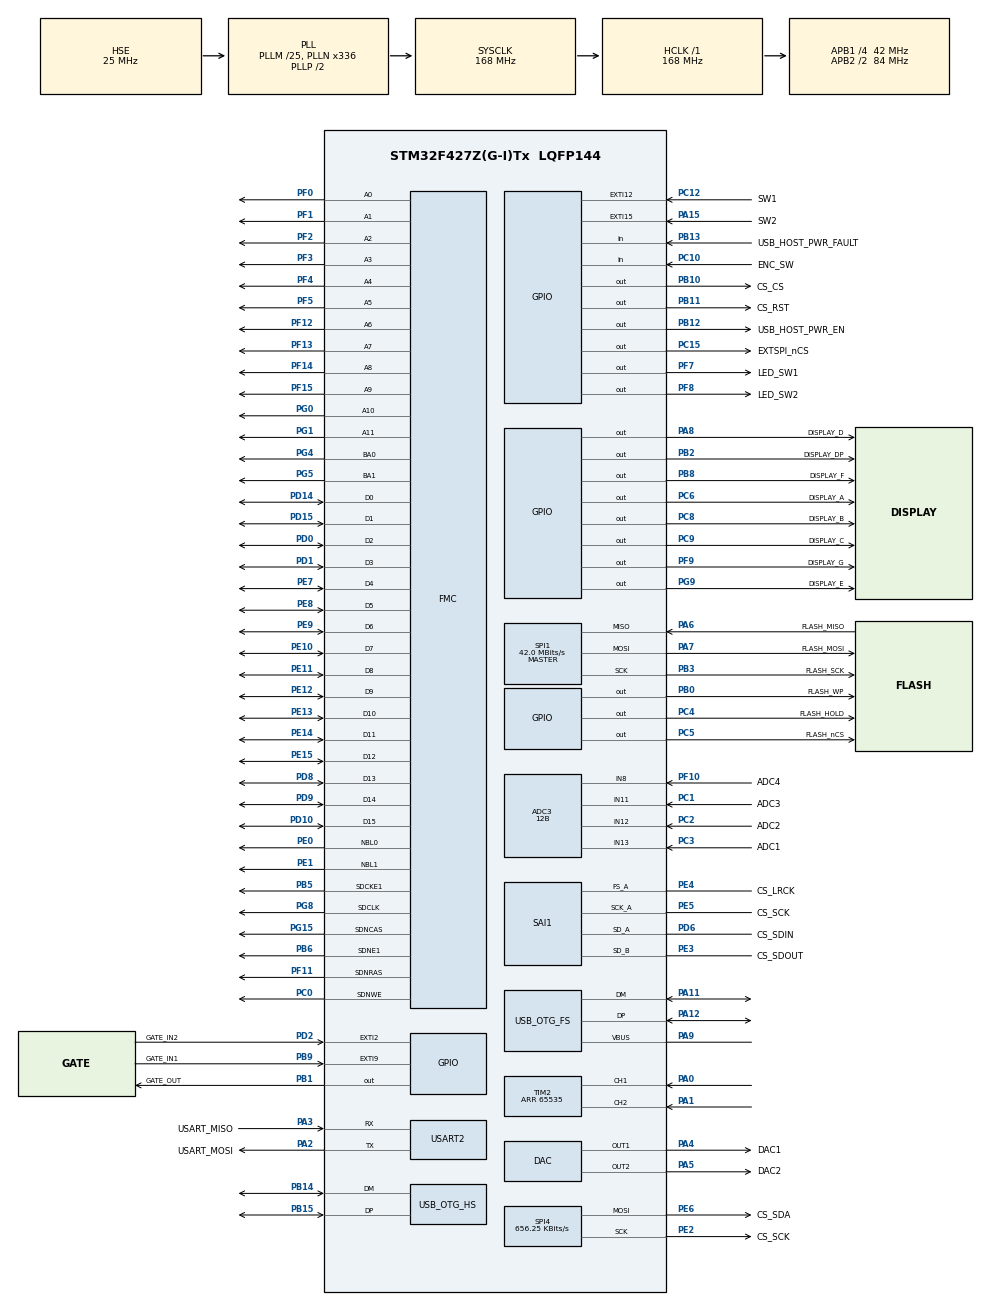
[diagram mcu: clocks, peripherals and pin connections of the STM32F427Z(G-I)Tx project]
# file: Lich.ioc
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ADC3.Channel-31\#ChannelRegularConversion=ADC_CHANNEL_13
ADC3.Channel-32\#ChannelRegularConversion=ADC_CHANNEL_12
ADC3.Channel-33\#ChannelRegularConversion=ADC_CHANNEL_11
ADC3.Channel-34\#ChannelRegularConversion=ADC_CHANNEL_8
ADC3.ClockPrescaler=ADC_CLOCK_SYNC_PCLK_DIV8
ADC3.ContinuousConvMode=ENABLE
ADC3.DMAContinuousRequests=ENABLE
ADC3.DataAlign=ADC_DATAALIGN_RIGHT
ADC3.DiscontinuousConvMode=DISABLE
ADC3.EOCSelection=ADC_EOC_SEQ_CONV
ADC3.EnableAnalogWatchDog=false
ADC3.ExternalTrigConv=ADC_SOFTWARE_START
ADC3.ExternalTrigConvEdge=ADC_EXTERNALTRIGCONVEDGE_NONE
ADC3.InjNumberOfConversion=0
ADC3.NbrOfConversion=4
ADC3.NbrOfConversionFlag=1
ADC3.Rank-31\#ChannelRegularConversion=1
ADC3.Rank-32\#ChannelRegularConversion=2
ADC3.Rank-33\#ChannelRegularConversion=3
ADC3.Rank-34\#ChannelRegularConversion=4
ADC3.Resolution=ADC_RESOLUTION_12B
ADC3.SamplingTime-31\#ChannelRegularConversion=ADC_SAMPLETIME_144CYCLES
ADC3.SamplingTime-32\#ChannelRegularConversion=ADC_SAMPLETIME_144CYCLES
ADC3.SamplingTime-33\#ChannelRegularConversion=ADC_SAMPLETIME_144CYCLES
ADC3.SamplingTime-34\#ChannelRegularConversion=ADC_SAMPLETIME_144CYCLES
ADC3.ScanConvMode=ENABLE
Dma.ADC3.2.Direction=DMA_PERIPH_TO_MEMORY
Dma.ADC3.2.FIFOMode=DMA_FIFOMODE_DISABLE
Dma.ADC3.2.Instance=DMA2_Stream0
Dma.ADC3.2.MemDataAlignment=DMA_MDATAALIGN_HALFWORD
Dma.ADC3.2.MemInc=DMA_MINC_ENABLE
Dma.ADC3.2.Mode=DMA_CIRCULAR
Dma.ADC3.2.PeriphDataAlignment=DMA_PDATAALIGN_HALFWORD
Dma.ADC3.2.PeriphInc=DMA_PINC_DISABLE
Dma.ADC3.2.Priority=DMA_PRIORITY_LOW
Dma.Request0=SAI1_A
Dma.Request1=SAI1_B
Dma.Request2=ADC3
Dma.Request3=USART2_RX
Dma.Request4=USART2_TX
Dma.SAI1_A.0.Direction=DMA_MEMORY_TO_PERIPH
Dma.SAI1_A.0.FIFOMode=DMA_FIFOMODE_DISABLE
Dma.SAI1_A.0.Instance=DMA2_Stream1
Dma.SAI1_A.0.MemDataAlignment=DMA_MDATAALIGN_WORD
Dma.SAI1_A.0.MemInc=DMA_MINC_ENABLE
Dma.SAI1_A.0.Mode=DMA_CIRCULAR
Dma.SAI1_A.0.PeriphDataAlignment=DMA_PDATAALIGN_WORD
Dma.SAI1_A.0.PeriphInc=DMA_PINC_DISABLE
Dma.SAI1_A.0.Priority=DMA_PRIORITY_VERY_HIGH
Dma.SAI1_B.1.Direction=DMA_PERIPH_TO_MEMORY
Dma.SAI1_B.1.FIFOMode=DMA_FIFOMODE_DISABLE
Dma.SAI1_B.1.Instance=DMA2_Stream4
Dma.SAI1_B.1.MemDataAlignment=DMA_MDATAALIGN_WORD
Dma.SAI1_B.1.MemInc=DMA_MINC_ENABLE
Dma.SAI1_B.1.Mode=DMA_CIRCULAR
Dma.SAI1_B.1.PeriphDataAlignment=DMA_PDATAALIGN_WORD
Dma.SAI1_B.1.PeriphInc=DMA_PINC_DISABLE
Dma.SAI1_B.1.Priority=DMA_PRIORITY_VERY_HIGH
Dma.USART2_RX.3.Direction=DMA_PERIPH_TO_MEMORY
Dma.USART2_RX.3.FIFOMode=DMA_FIFOMODE_DISABLE
Dma.USART2_RX.3.Instance=DMA1_Stream5
Dma.USART2_RX.3.MemDataAlignment=DMA_MDATAALIGN_BYTE
Dma.USART2_RX.3.MemInc=DMA_MINC_ENABLE
Dma.USART2_RX.3.Mode=DMA_NORMAL
Dma.USART2_RX.3.PeriphDataAlignment=DMA_PDATAALIGN_BYTE
Dma.USART2_RX.3.PeriphInc=DMA_PINC_DISABLE
Dma.USART2_RX.3.Priority=DMA_PRIORITY_LOW
Dma.USART2_TX.4.Direction=DMA_MEMORY_TO_PERIPH
Dma.USART2_TX.4.FIFOMode=DMA_FIFOMODE_DISABLE
Dma.USART2_TX.4.Instance=DMA1_Stream6
Dma.USART2_TX.4.MemDataAlignment=DMA_MDATAALIGN_BYTE
Dma.USART2_TX.4.MemInc=DMA_MINC_ENABLE
Dma.USART2_TX.4.Mode=DMA_NORMAL
Dma.USART2_TX.4.PeriphDataAlignment=DMA_PDATAALIGN_BYTE
Dma.USART2_TX.4.PeriphInc=DMA_PINC_DISABLE
Dma.USART2_TX.4.Priority=DMA_PRIORITY_LOW
FMC.CASLatency1=FMC_SDRAM_CAS_LATENCY_3
FMC.ExitSelfRefreshDelay1=6
FMC.LoadToActiveDelay1=2
FMC.RCDDelay1=2
FMC.RPDelay1=2
FMC.RPDelay2=2
FMC.ReadBurst1=FMC_SDRAM_RBURST_ENABLE
FMC.ReadBurst2=FMC_SDRAM_RBURST_ENABLE
FMC.ReadPipeDelay1=FMC_SDRAM_RPIPE_DELAY_0
FMC.RowCycleDelay1=6
FMC.RowCycleDelay2=6
FMC.SDClockPeriod1=FMC_SDRAM_CLOCK_PERIOD_2
FMC.SDClockPeriod2=FMC_SDRAM_CLOCK_PERIOD_2
FMC.SelfRefreshTime1=4
FMC.WriteRecoveryTime1=2
FREERTOS.INCLUDE_vTaskDelayUntil=1
FREERTOS.MEMORY_ALLOCATION=2
FREERTOS.Tasks01=defaultTask,0,1024,StartDefaultTask,Default,NULL,Dynamic,NULL,NULL
FREERTOS.configCHECK_FOR_STACK_OVERFLOW=2
FREERTOS.configENABLE_BACKWARD_COMPATIBILITY=0
FREERTOS.configTOTAL_HEAP_SIZE=8192
FREERTOS.configUSE_MALLOC_FAILED_HOOK=1
FREERTOS.configUSE_MUTEXES=0
FREERTOS.configUSE_PREEMPTION=0
Mcu.Family=STM32F4
Mcu.Name=STM32F427Z(G-I)Tx
Mcu.Package=LQFP144
NVIC.DMA1_Stream5_IRQn=true\:5\:0\:false\:false\:true\:true\:false\:true
NVIC.DMA1_Stream6_IRQn=true\:5\:0\:false\:false\:true\:true\:false\:true
NVIC.DMA2_Stream0_IRQn=true\:10\:0\:true\:false\:true\:true\:true\:true
NVIC.DMA2_Stream1_IRQn=true\:5\:0\:true\:false\:true\:true\:true\:true
NVIC.DMA2_Stream4_IRQn=true\:5\:0\:true\:false\:true\:true\:true\:true
NVIC.EXTI15_10_IRQn=true\:10\:0\:true\:false\:true\:true\:true\:true
NVIC.EXTI2_IRQn=true\:10\:0\:true\:false\:true\:true\:true\:true
NVIC.EXTI9_5_IRQn=true\:10\:0\:true\:false\:true\:true\:true\:true
NVIC.OTG_FS_IRQn=true\:5\:0\:false\:false\:true\:true\:true\:true
NVIC.OTG_HS_IRQn=true\:8\:0\:true\:false\:true\:true\:true\:true
NVIC.PriorityGroup=NVIC_PRIORITYGROUP_4
NVIC.SAI1_IRQn=true\:5\:0\:true\:false\:true\:true\:true\:true
NVIC.USART2_IRQn=true\:5\:0\:false\:false\:true\:true\:true\:true
PA0/WKUP.GPIO_PuPd=GPIO_PULLUP
PA0/WKUP.Signal=S_TIM2_CH1_ETR
PA1.GPIO_PuPd=GPIO_PULLUP
PA1.Signal=S_TIM2_CH2
PA11.Mode=Device_Only
PA11.Signal=USB_OTG_FS_DM
PA12.Mode=Device_Only
PA12.Signal=USB_OTG_FS_DP
PA13.GPIO_Label=SWDIO
PA13.Mode=Serial_Wire
PA13.Signal=SYS_JTMS-SWDIO
PA14.GPIO_Label=SWCLK
PA14.Mode=Serial_Wire
PA14.Signal=SYS_JTCK-SWCLK
PA15.GPIO_Label=SW2
PA15.GPIO_ModeDefaultEXTI=GPIO_MODE_IT_RISING_FALLING
PA15.GPIO_PuPd=GPIO_PULLUP
PA15.Signal=GPXTI15
PA2.GPIO_Label=USART_MOSI
PA2.Mode=Asynchronous
PA2.Signal=USART2_TX
PA3.GPIO_Label=USART_MISO
PA3.Mode=Asynchronous
PA3.Signal=USART2_RX
PA4.GPIO_Label=DAC1
PA4.Signal=COMP_DAC1_group
PA5.GPIO_Label=DAC2
PA5.Signal=COMP_DAC2_group
PA6.GPIO_Label=FLASH_MISO
PA6.Mode=Full_Duplex_Master
PA6.Signal=SPI1_MISO
PA7.GPIO_Label=FLASH_MOSI
PA7.Mode=Full_Duplex_Master
PA7.Signal=SPI1_MOSI
PA8.GPIO_Label=DISPLAY_D
PA8.Signal=GPIO_Output
PA9.Mode=Activate_VBUS
PA9.Signal=USB_OTG_FS_VBUS
PB0.GPIO_Label=FLASH_WP
PB0.Signal=GPIO_Output
PB1.GPIO_Label=GATE_OUT
PB1.Signal=GPIO_Output
PB10.GPIO_Label=CS_CS
PB10.Signal=GPIO_Output
PB11.GPIO_Label=CS_RST
PB11.Signal=GPIO_Output
PB12.GPIO_Label=USB_HOST_PWR_EN
PB12.Signal=GPIO_Output
PB13.GPIO_Label=USB_HOST_PWR_FAULT
PB13.Signal=GPIO_Input
PB14.Mode=Host_FS
PB14.Signal=USB_OTG_HS_DM
PB15.Mode=Host_FS
PB15.Signal=USB_OTG_HS_DP
PB2/BOOT1.GPIO_Label=DISPLAY_DP
PB2/BOOT1.Signal=GPIO_Output
PB3.GPIO_Label=FLASH_SCK
PB3.Mode=Full_Duplex_Master
PB3.Signal=SPI1_SCK
PB5.Mode=SdramChipSelect2_1
PB5.Signal=FMC_SDCKE1
PB6.Mode=SdramChipSelect2_1
PB6.Signal=FMC_SDNE1
PB8.GPIO_Label=DISPLAY_F
PB8.Signal=GPIO_Output
PB9.GPIO_Label=GATE_IN1
PB9.GPIO_ModeDefaultEXTI=GPIO_MODE_IT_RISING_FALLING
PB9.GPIO_PuPd=GPIO_PULLUP
PB9.Signal=GPXTI9
PC0.Signal=FMC_SDNWE
PC1.GPIO_Label=ADC3
PC1.Signal=ADCx_IN11
PC10.GPIO_Label=ENC_SW
PC10.GPIO_PuPd=GPIO_PULLUP
PC10.Signal=GPIO_Input
PC12.GPIO_Label=SW1
PC12.GPIO_ModeDefaultEXTI=GPIO_MODE_IT_RISING_FALLING
PC12.GPIO_PuPd=GPIO_PULLUP
PC12.Signal=GPXTI12
PC15/OSC32_OUT.GPIO_Label=EXTSPI_nCS
PC15/OSC32_OUT.Signal=GPIO_Output
PC2.GPIO_Label=ADC2
PC2.Signal=ADCx_IN12
PC3.GPIO_Label=ADC1
PC3.Signal=ADCx_IN13
PC4.GPIO_Label=FLASH_HOLD
PC4.Signal=GPIO_Output
PC5.GPIO_Label=FLASH_nCS
PC5.Signal=GPIO_Output
PC6.GPIO_Label=DISPLAY_A
PC6.PinState=GPIO_PIN_SET
PC6.Signal=GPIO_Output
PC8.GPIO_Label=DISPLAY_B
PC8.Signal=GPIO_Output
PC9.GPIO_Label=DISPLAY_C
PC9.Signal=GPIO_Output
PD0.Signal=FMC_D2_DA2
PD1.Signal=FMC_D3_DA3
PD10.Signal=FMC_D15_DA15
PD14.Signal=FMC_D0_DA0
PD15.Signal=FMC_D1_DA1
PD2.GPIO_Label=GATE_IN2
PD2.GPIO_ModeDefaultEXTI=GPIO_MODE_IT_RISING_FALLING
PD2.GPIO_PuPd=GPIO_PULLUP
PD2.Signal=GPXTI2
PD6.GPIO_Label=CS_SDIN
PD6.Mode=SAI_A_AsyncSlave
PD6.Signal=SAI1_SD_A
PD8.Signal=FMC_D13_DA13
PD9.Signal=FMC_D14_DA14
PE0.Signal=FMC_NBL0
PE1.Signal=FMC_NBL1
PE10.Signal=FMC_D7_DA7
PE11.Signal=FMC_D8_DA8
PE12.Signal=FMC_D9_DA9
PE13.Signal=FMC_D10_DA10
PE14.Signal=FMC_D11_DA11
PE15.Signal=FMC_D12_DA12
PE2.GPIO_Label=CS_SCK
PE2.Mode=TX_Only_Simplex_Unidirect_Master
PE2.Signal=SPI4_SCK
PE3.GPIO_Label=CS_SDOUT
PE3.Mode=SAI_B_SyncSlave
PE3.Signal=SAI1_SD_B
PE4.GPIO_Label=CS_LRCK
PE4.Mode=SAI_A_AsyncSlave
PE4.Signal=SAI1_FS_A
PE5.GPIO_Label=CS_SCK
PE5.Mode=SAI_A_AsyncSlave
PE5.Signal=SAI1_SCK_A
PE6.GPIO_Label=CS_SDA
PE6.Mode=TX_Only_Simplex_Unidirect_Master
PE6.Signal=SPI4_MOSI
PE7.Signal=FMC_D4_DA4
PE8.Signal=FMC_D5_DA5
PE9.Signal=FMC_D6_DA6
PF0.Signal=FMC_A0
PF1.Signal=FMC_A1
PF10.GPIO_Label=ADC4
PF10.Mode=IN8
PF10.Signal=ADC3_IN8
PF11.Signal=FMC_SDNRAS
PF12.Signal=FMC_A6
PF13.Signal=FMC_A7
PF14.Signal=FMC_A8
PF15.Signal=FMC_A9
PF2.Signal=FMC_A2
PF3.Signal=FMC_A3
PF4.Signal=FMC_A4
PF5.Signal=FMC_A5
PF7.GPIO_Label=LED_SW1
PF7.Signal=GPIO_Output
PF8.GPIO_Label=LED_SW2
PF8.Signal=GPIO_Output
PF9.GPIO_Label=DISPLAY_G
PF9.Signal=GPIO_Output
PG0.Signal=FMC_A10
PG1.Signal=FMC_A11
PG15.Signal=FMC_SDNCAS
PG4.Signal=FMC_A14_BA0
PG5.Signal=FMC_A15_BA1
PG8.Signal=FMC_SDCLK
PG9.GPIO_Label=DISPLAY_E
PG9.Signal=GPIO_Output
PH0/OSC_IN.GPIO_Label=OSC1
PH0/OSC_IN.Mode=HSE-External-Oscillator
PH0/OSC_IN.Signal=RCC_OSC_IN
PH1/OSC_OUT.GPIO_Label=OSC2
PH1/OSC_OUT.Mode=HSE-External-Oscillator
PH1/OSC_OUT.Signal=RCC_OSC_OUT
ProjectManager.HeapSize=0x200
ProjectManager.StackSize=0x400
ProjectManager.TargetToolchain=Other Toolchains (GPDSC)
RCC.48MHZClocksFreq_Value=48000000
RCC.AHBFreq_Value=168000000
RCC.APB1CLKDivider=RCC_HCLK_DIV4
RCC.APB1Freq_Value=42000000
RCC.APB1TimFreq_Value=84000000
RCC.APB2CLKDivider=RCC_HCLK_DIV2
RCC.APB2Freq_Value=84000000
RCC.APB2TimFreq_Value=168000000
RCC.CortexFreq_Value=168000000
RCC.HCLKFreq_Value=168000000
RCC.HSE_VALUE=25000000
RCC.HSI_VALUE=16000000
RCC.LSE_VALUE=32768
RCC.PLLM=25
RCC.PLLN=336
RCC.PLLQ=7
RCC.PLLSAIN=100
RCC.SYSCLKFreq_VALUE=168000000
RCC.SYSCLKSource=RCC_SYSCLKSOURCE_PLLCLK
RCC.USBFreq_Value=48000000
RCC.VCOOutputFreq_Value=336000000
SAI1.AudioMode-SAI_A_AsyncSlave=SAI_MODESLAVE_TX
SAI1.AudioMode-SAI_B_SyncSlave=SAI_MODESLAVE_RX
SAI1.DataSize-SAI_A_AsyncSlave=SAI_DATASIZE_24
SAI1.FSDefinition-SAI_A_AsyncSlave=SAI_FS_CHANNEL_IDENTIFICATION
SAI1.FSDefinition-SAI_B_SyncSlave=SAI_FS_CHANNEL_IDENTIFICATION
SAI1.FrameLength-SAI_A_AsyncSlave=64
SAI1.FrameLength-SAI_B_SyncSlave=64
SAI1.Instance-SAI_A_AsyncSlave=SAI$Index_Block_A
SAI1.Instance-SAI_B_SyncSlave=SAI$Index_Block_B
SAI1.SlotNumber-SAI_A_AsyncSlave=2
SAI1.SlotSize-SAI_A_AsyncSlave=SAI_SLOTSIZE_32B
SAI1.SlotSize-SAI_B_SyncSlave=SAI_SLOTSIZE_32B
SAI1.Synchro-SAI_A_AsyncSlave=SAI_ASYNCHRONOUS
SAI1.Synchro-SAI_B_SyncSlave=SAI_SYNCHRONOUS
SAI1.Synchro_A=SAI_ASYNCHRONOUS
SAI1.Synchro_B=SAI_SYNCHRONOUS
SAI1.VirtualMode-SAI_A_AsyncSlave=VM_SLAVE
SAI1.VirtualMode-SAI_B_SyncSlave=VM_SLAVE
SH.ADCx_IN11.0=ADC3_IN11,IN11
SH.ADCx_IN12.0=ADC3_IN12,IN12
SH.ADCx_IN13.0=ADC3_IN13,IN13
SH.COMP_DAC1_group.0=DAC_OUT1,DAC_OUT1
SH.COMP_DAC2_group.0=DAC_OUT2,DAC_OUT2
SH.FMC_A0.0=FMC_A0,12b-sda1
SH.FMC_A1.0=FMC_A1,12b-sda1
SH.FMC_A10.0=FMC_A10,12b-sda1
SH.FMC_A11.0=FMC_A11,12b-sda1
SH.FMC_A14_BA0.0=FMC_BA0,FourSdramBanks1
SH.FMC_A15_BA1.0=FMC_BA1,FourSdramBanks1
SH.FMC_A2.0=FMC_A2,12b-sda1
SH.FMC_A3.0=FMC_A3,12b-sda1
SH.FMC_A4.0=FMC_A4,12b-sda1
SH.FMC_A5.0=FMC_A5,12b-sda1
SH.FMC_A6.0=FMC_A6,12b-sda1
SH.FMC_A7.0=FMC_A7,12b-sda1
SH.FMC_A8.0=FMC_A8,12b-sda1
SH.FMC_A9.0=FMC_A9,12b-sda1
SH.FMC_D0_DA0.0=FMC_D0,sd-16b-d1
SH.FMC_D10_DA10.0=FMC_D10,sd-16b-d1
SH.FMC_D11_DA11.0=FMC_D11,sd-16b-d1
SH.FMC_D12_DA12.0=FMC_D12,sd-16b-d1
SH.FMC_D13_DA13.0=FMC_D13,sd-16b-d1
SH.FMC_D14_DA14.0=FMC_D14,sd-16b-d1
SH.FMC_D15_DA15.0=FMC_D15,sd-16b-d1
SH.FMC_D1_DA1.0=FMC_D1,sd-16b-d1
SH.FMC_D2_DA2.0=FMC_D2,sd-16b-d1
SH.FMC_D3_DA3.0=FMC_D3,sd-16b-d1
SH.FMC_D4_DA4.0=FMC_D4,sd-16b-d1
SH.FMC_D5_DA5.0=FMC_D5,sd-16b-d1
SH.FMC_D6_DA6.0=FMC_D6,sd-16b-d1
SH.FMC_D7_DA7.0=FMC_D7,sd-16b-d1
SH.FMC_D8_DA8.0=FMC_D8,sd-16b-d1
SH.FMC_D9_DA9.0=FMC_D9,sd-16b-d1
SH.FMC_NBL0.0=FMC_NBL0,Sd2ByteEnable1
SH.FMC_NBL1.0=FMC_NBL1,Sd2ByteEnable1
SH.FMC_SDCLK.0=FMC_SDCLK,12b-sda1
SH.FMC_SDNCAS.0=FMC_SDNCAS,12b-sda1
SH.FMC_SDNRAS.0=FMC_SDNRAS,12b-sda1
SH.FMC_SDNWE.0=FMC_SDNWE,12b-sda1
SH.S_TIM2_CH1_ETR.0=TIM2_CH1,Encoder_Interface
SH.S_TIM2_CH2.0=TIM2_CH2,Encoder_Interface
SPI1.CalculateBaudRate=42.0 MBits/s
SPI1.Direction=SPI_DIRECTION_2LINES
SPI1.Mode=SPI_MODE_MASTER
SPI1.VirtualType=VM_MASTER
SPI4.BaudRatePrescaler=SPI_BAUDRATEPRESCALER_128
SPI4.CalculateBaudRate=656.25 KBits/s
SPI4.Direction=SPI_DIRECTION_2LINES
SPI4.Mode=SPI_MODE_MASTER
SPI4.VirtualType=VM_MASTER
TIM2.EncoderMode=TIM_ENCODERMODE_TI12
TIM2.Period=65535
TIM2.TIM_MasterOutputTrigger=TIM_TRGO_RESET
USART2.VirtualMode=VM_ASYNC
USB_OTG_FS.VirtualMode=Device_Only
USB_OTG_HS.VirtualMode-Host_FS=Host_FS
VP_FREERTOS_VS_CMSIS_V1.Mode=CMSIS_V1
VP_RTC_VS_RTC_Activate.Mode=RTC_Enabled
board=Lich

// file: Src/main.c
/* USER CODE BEGIN Header */
/**
  * @brief  Function implementing the defaultTask thread.
  * @param  argument: Not used
  * @retval None
  */
/* USER CODE END Header */
#include "main.h"
#include "cmsis_os.h"

/* USER CODE BEGIN Includes */

#include "errorhandlers.h"

#define REFRESH_COUNT       ((uint32_t)0x0569)   /* SDRAM refresh counter (90MHz SD clock) */

/* USER CODE END Includes */

ADC_HandleTypeDef hadc3;
DMA_HandleTypeDef hdma_adc3;

DAC_HandleTypeDef hdac;

RTC_HandleTypeDef hrtc;

SAI_HandleTypeDef hsai_BlockA1;
SAI_HandleTypeDef hsai_BlockB1;
DMA_HandleTypeDef hdma_sai1_a;
DMA_HandleTypeDef hdma_sai1_b;

SPI_HandleTypeDef hspi1;
SPI_HandleTypeDef hspi4;

TIM_HandleTypeDef htim2;

UART_HandleTypeDef huart2;
DMA_HandleTypeDef hdma_usart2_rx;
DMA_HandleTypeDef hdma_usart2_tx;

PCD_HandleTypeDef hpcd_USB_OTG_FS;
HCD_HandleTypeDef hhcd_USB_OTG_HS;

SDRAM_HandleTypeDef hsdram1;

osThreadId defaultTaskHandle;
/* USER CODE BEGIN PV */
/* Private variables ---------------------------------------------------------*/

/* USER CODE END PV */

void SystemClock_Config(void);
void PeriphCommonClock_Config(void);
static void MX_GPIO_Init(void);
static void MX_DMA_Init(void);
static void MX_ADC3_Init(void);
static void MX_FMC_Init(void);
static void MX_SAI1_Init(void);
static void MX_SPI4_Init(void);
static void MX_TIM2_Init(void);
static void MX_USART2_UART_Init(void);
static void MX_DAC_Init(void);
static void MX_SPI1_Init(void);
static void MX_RTC_Init(void);
static void MX_USB_OTG_FS_PCD_Init(void);
static void MX_USB_OTG_HS_HCD_Init(void);
void StartDefaultTask(void const * argument);

/* USER CODE BEGIN PFP */
/* Private function prototypes -----------------------------------------------*/

void setup(void);
void loop(void);
void SDRAM_Initialization_Sequence(SDRAM_HandleTypeDef *hsdram);

/* USER CODE END PFP */

int main(void)
{

  /* MCU Configuration--------------------------------------------------------*/

  /* Reset of all peripherals, Initializes the Flash interface and the Systick. */
  HAL_Init();

  /* Configure the system clock */
  SystemClock_Config();

/* Configure the peripherals common clocks */
  PeriphCommonClock_Config();

  /* Initialize all configured peripherals */
  MX_GPIO_Init();
  MX_DMA_Init();
  MX_ADC3_Init();
  MX_FMC_Init();
  MX_SAI1_Init();
  MX_SPI4_Init();
  MX_TIM2_Init();
  MX_USART2_UART_Init();
  MX_DAC_Init();
  MX_SPI1_Init();
  MX_RTC_Init();
  MX_USB_OTG_FS_PCD_Init();
  MX_USB_OTG_HS_HCD_Init();
  /* USER CODE BEGIN 2 */

  HAL_SAI_DeInit(&hsai_BlockA1);
  HAL_SAI_DeInit(&hsai_BlockB1);
  hsai_BlockA1.Instance = SAI1_Block_A;
  hsai_BlockA1.Init.AudioMode = SAI_MODESLAVE_TX;
  hsai_BlockA1.Init.Synchro = SAI_ASYNCHRONOUS;
  hsai_BlockA1.Init.OutputDrive = SAI_OUTPUTDRIVE_DISABLE;
  hsai_BlockA1.Init.FIFOThreshold = SAI_FIFOTHRESHOLD_EMPTY;
  hsai_BlockA1.Init.SynchroExt = SAI_SYNCEXT_DISABLE;
  hsai_BlockA1.Init.MonoStereoMode = SAI_STEREOMODE;
  hsai_BlockA1.Init.CompandingMode = SAI_NOCOMPANDING;
  hsai_BlockA1.Init.TriState = SAI_OUTPUT_NOTRELEASED;
  if (HAL_SAI_InitProtocol(&hsai_BlockA1, SAI_I2S_STANDARD, SAI_PROTOCOL_DATASIZE_24BIT, 2) != HAL_OK)
    Error_Handler();
  hsai_BlockB1.Instance = SAI1_Block_B;
  hsai_BlockB1.Init.AudioMode = SAI_MODESLAVE_RX;
  hsai_BlockB1.Init.Synchro = SAI_SYNCHRONOUS;
  hsai_BlockB1.Init.OutputDrive = SAI_OUTPUTDRIVE_DISABLE;
  hsai_BlockB1.Init.FIFOThreshold = SAI_FIFOTHRESHOLD_EMPTY;
  hsai_BlockB1.Init.SynchroExt = SAI_SYNCEXT_DISABLE;
  hsai_BlockB1.Init.MonoStereoMode = SAI_STEREOMODE;
  hsai_BlockB1.Init.CompandingMode = SAI_NOCOMPANDING;
  hsai_BlockB1.Init.TriState = SAI_OUTPUT_NOTRELEASED;
  if (HAL_SAI_InitProtocol(&hsai_BlockB1, SAI_I2S_STANDARD, SAI_PROTOCOL_DATASIZE_24BIT, 2) != HAL_OK)
    Error_Handler();

  SDRAM_Initialization_Sequence(&hsdram1);

  /* USER CODE END 2 */

  /* Create the thread(s) */
  /* definition and creation of defaultTask */
  osThreadDef(defaultTask, StartDefaultTask, osPriorityNormal, 0, 1024);
  defaultTaskHandle = osThreadCreate(osThread(defaultTask), NULL);

  /* Start scheduler */
  osKernelStart();

  /* We should never get here as control is now taken by the scheduler */
  /* Infinite loop */
  while (1)
  {

  }
}

void SystemClock_Config(void)
{
  RCC_OscInitTypeDef RCC_OscInitStruct = {0};
  RCC_ClkInitTypeDef RCC_ClkInitStruct = {0};

  /** Macro to configure SAI1BlockB clock source selection
  */
  __HAL_RCC_SAI_BLOCKBCLKSOURCE_CONFIG(SAI_CLKSOURCE_PLLSAI);
  /** Macro to configure SAI1BlockA clock source selection
  */
  __HAL_RCC_SAI_BLOCKACLKSOURCE_CONFIG(SAI_CLKSOURCE_PLLSAI);
  /** Configure the main internal regulator output voltage
  */
  __HAL_RCC_PWR_CLK_ENABLE();
  __HAL_PWR_VOLTAGESCALING_CONFIG(PWR_REGULATOR_VOLTAGE_SCALE1);
  /** Initializes the RCC Oscillators according to the specified parameters
  * in the RCC_OscInitTypeDef structure.
  */
  RCC_OscInitStruct.OscillatorType = RCC_OSCILLATORTYPE_LSI|RCC_OSCILLATORTYPE_HSE;
  RCC_OscInitStruct.HSEState = RCC_HSE_ON;
  RCC_OscInitStruct.LSIState = RCC_LSI_ON;
  RCC_OscInitStruct.PLL.PLLState = RCC_PLL_ON;
  RCC_OscInitStruct.PLL.PLLSource = RCC_PLLSOURCE_HSE;
  RCC_OscInitStruct.PLL.PLLM = 25;
  RCC_OscInitStruct.PLL.PLLN = 336;
  RCC_OscInitStruct.PLL.PLLP = RCC_PLLP_DIV2;
  RCC_OscInitStruct.PLL.PLLQ = 7;
  if (HAL_RCC_OscConfig(&RCC_OscInitStruct) != HAL_OK)
  {
    Error_Handler();
  }
  /** Initializes the CPU, AHB and APB buses clocks
  */
  RCC_ClkInitStruct.ClockType = RCC_CLOCKTYPE_HCLK|RCC_CLOCKTYPE_SYSCLK
                              |RCC_CLOCKTYPE_PCLK1|RCC_CLOCKTYPE_PCLK2;
  RCC_ClkInitStruct.SYSCLKSource = RCC_SYSCLKSOURCE_PLLCLK;
  RCC_ClkInitStruct.AHBCLKDivider = RCC_SYSCLK_DIV1;
  RCC_ClkInitStruct.APB1CLKDivider = RCC_HCLK_DIV4;
  RCC_ClkInitStruct.APB2CLKDivider = RCC_HCLK_DIV2;

  if (HAL_RCC_ClockConfig(&RCC_ClkInitStruct, FLASH_LATENCY_5) != HAL_OK)
  {
    Error_Handler();
  }
}

void PeriphCommonClock_Config(void)
{
  RCC_PeriphCLKInitTypeDef PeriphClkInitStruct = {0};

  /** Initializes the peripherals clock
  */
  PeriphClkInitStruct.PeriphClockSelection = RCC_PERIPHCLK_SAI_PLLSAI;
  PeriphClkInitStruct.PLLSAI.PLLSAIN = 100;
  PeriphClkInitStruct.PLLSAI.PLLSAIQ = 4;
  PeriphClkInitStruct.PLLSAIDivQ = 1;
  if (HAL_RCCEx_PeriphCLKConfig(&PeriphClkInitStruct) != HAL_OK)
  {
    Error_Handler();
  }
}

static void MX_ADC3_Init(void)
{

  ADC_ChannelConfTypeDef sConfig = {0};

  /** Configure the global features of the ADC (Clock, Resolution, Data Alignment and number of conversion)
  */
  hadc3.Instance = ADC3;
  hadc3.Init.ClockPrescaler = ADC_CLOCK_SYNC_PCLK_DIV8;
  hadc3.Init.Resolution = ADC_RESOLUTION_12B;
  hadc3.Init.ScanConvMode = ENABLE;
  hadc3.Init.ContinuousConvMode = ENABLE;
  hadc3.Init.DiscontinuousConvMode = DISABLE;
  hadc3.Init.ExternalTrigConvEdge = ADC_EXTERNALTRIGCONVEDGE_NONE;
  hadc3.Init.ExternalTrigConv = ADC_SOFTWARE_START;
  hadc3.Init.DataAlign = ADC_DATAALIGN_RIGHT;
  hadc3.Init.NbrOfConversion = 4;
  hadc3.Init.DMAContinuousRequests = ENABLE;
  hadc3.Init.EOCSelection = ADC_EOC_SEQ_CONV;
  if (HAL_ADC_Init(&hadc3) != HAL_OK)
  {
    Error_Handler();
  }
  /** Configure for the selected ADC regular channel its corresponding rank in the sequencer and its sample time.
  */
  sConfig.Channel = ADC_CHANNEL_13;
  sConfig.Rank = 1;
  sConfig.SamplingTime = ADC_SAMPLETIME_144CYCLES;
  if (HAL_ADC_ConfigChannel(&hadc3, &sConfig) != HAL_OK)
  {
    Error_Handler();
  }
  /** Configure for the selected ADC regular channel its corresponding rank in the sequencer and its sample time.
  */
  sConfig.Channel = ADC_CHANNEL_12;
  sConfig.Rank = 2;
  if (HAL_ADC_ConfigChannel(&hadc3, &sConfig) != HAL_OK)
  {
    Error_Handler();
  }
  /** Configure for the selected ADC regular channel its corresponding rank in the sequencer and its sample time.
  */
  sConfig.Channel = ADC_CHANNEL_11;
  sConfig.Rank = 3;
  if (HAL_ADC_ConfigChannel(&hadc3, &sConfig) != HAL_OK)
  {
    Error_Handler();
  }
  /** Configure for the selected ADC regular channel its corresponding rank in the sequencer and its sample time.
  */
  sConfig.Channel = ADC_CHANNEL_8;
  sConfig.Rank = 4;
  if (HAL_ADC_ConfigChannel(&hadc3, &sConfig) != HAL_OK)
  {
    Error_Handler();
  }

}

static void MX_DAC_Init(void)
{

  DAC_ChannelConfTypeDef sConfig = {0};

  /** DAC Initialization
  */
  hdac.Instance = DAC;
  if (HAL_DAC_Init(&hdac) != HAL_OK)
  {
    Error_Handler();
  }
  /** DAC channel OUT1 config
  */
  sConfig.DAC_Trigger = DAC_TRIGGER_NONE;
  sConfig.DAC_OutputBuffer = DAC_OUTPUTBUFFER_ENABLE;
  if (HAL_DAC_ConfigChannel(&hdac, &sConfig, DAC_CHANNEL_1) != HAL_OK)
  {
    Error_Handler();
  }
  /** DAC channel OUT2 config
  */
  if (HAL_DAC_ConfigChannel(&hdac, &sConfig, DAC_CHANNEL_2) != HAL_OK)
  {
    Error_Handler();
  }

}

static void MX_RTC_Init(void)
{

  /** Initialize RTC Only
  */
  hrtc.Instance = RTC;
  hrtc.Init.HourFormat = RTC_HOURFORMAT_24;
  hrtc.Init.AsynchPrediv = 127;
  hrtc.Init.SynchPrediv = 255;
  hrtc.Init.OutPut = RTC_OUTPUT_DISABLE;
  hrtc.Init.OutPutPolarity = RTC_OUTPUT_POLARITY_HIGH;
  hrtc.Init.OutPutType = RTC_OUTPUT_TYPE_OPENDRAIN;
  if (HAL_RTC_Init(&hrtc) != HAL_OK)
  {
    Error_Handler();
  }

}

static void MX_SAI1_Init(void)
{

  hsai_BlockA1.Instance = SAI1_Block_A;
  hsai_BlockA1.Init.Protocol = SAI_FREE_PROTOCOL;
  hsai_BlockA1.Init.AudioMode = SAI_MODESLAVE_TX;
  hsai_BlockA1.Init.DataSize = SAI_DATASIZE_24;
  hsai_BlockA1.Init.FirstBit = SAI_FIRSTBIT_MSB;
  hsai_BlockA1.Init.ClockStrobing = SAI_CLOCKSTROBING_FALLINGEDGE;
  hsai_BlockA1.Init.Synchro = SAI_ASYNCHRONOUS;
  hsai_BlockA1.Init.OutputDrive = SAI_OUTPUTDRIVE_DISABLE;
  hsai_BlockA1.Init.FIFOThreshold = SAI_FIFOTHRESHOLD_EMPTY;
  hsai_BlockA1.FrameInit.FrameLength = 64;
  hsai_BlockA1.FrameInit.ActiveFrameLength = 1;
  hsai_BlockA1.FrameInit.FSDefinition = SAI_FS_CHANNEL_IDENTIFICATION;
  hsai_BlockA1.FrameInit.FSPolarity = SAI_FS_ACTIVE_LOW;
  hsai_BlockA1.FrameInit.FSOffset = SAI_FS_FIRSTBIT;
  hsai_BlockA1.SlotInit.FirstBitOffset = 0;
  hsai_BlockA1.SlotInit.SlotSize = SAI_SLOTSIZE_32B;
  hsai_BlockA1.SlotInit.SlotNumber = 2;
  hsai_BlockA1.SlotInit.SlotActive = 0x00000000;
  if (HAL_SAI_Init(&hsai_BlockA1) != HAL_OK)
  {
    Error_Handler();
  }
  hsai_BlockB1.Instance = SAI1_Block_B;
  hsai_BlockB1.Init.Protocol = SAI_FREE_PROTOCOL;
  hsai_BlockB1.Init.AudioMode = SAI_MODESLAVE_RX;
  hsai_BlockB1.Init.DataSize = SAI_DATASIZE_24;
  hsai_BlockB1.Init.FirstBit = SAI_FIRSTBIT_MSB;
  hsai_BlockB1.Init.ClockStrobing = SAI_CLOCKSTROBING_FALLINGEDGE;
  hsai_BlockB1.Init.Synchro = SAI_SYNCHRONOUS;
  hsai_BlockB1.Init.OutputDrive = SAI_OUTPUTDRIVE_DISABLE;
  hsai_BlockB1.Init.FIFOThreshold = SAI_FIFOTHRESHOLD_EMPTY;
  hsai_BlockB1.FrameInit.FrameLength = 64;
  hsai_BlockB1.FrameInit.ActiveFrameLength = 1;
  hsai_BlockB1.FrameInit.FSDefinition = SAI_FS_CHANNEL_IDENTIFICATION;
  hsai_BlockB1.FrameInit.FSPolarity = SAI_FS_ACTIVE_LOW;
  hsai_BlockB1.FrameInit.FSOffset = SAI_FS_FIRSTBIT;
  hsai_BlockB1.SlotInit.FirstBitOffset = 0;
  hsai_BlockB1.SlotInit.SlotSize = SAI_SLOTSIZE_32B;
  hsai_BlockB1.SlotInit.SlotNumber = 2;
  hsai_BlockB1.SlotInit.SlotActive = 0x00000000;
  if (HAL_SAI_Init(&hsai_BlockB1) != HAL_OK)
  {
    Error_Handler();
  }

}

static void MX_SPI1_Init(void)
{

  /* SPI1 parameter configuration*/
  hspi1.Instance = SPI1;
  hspi1.Init.Mode = SPI_MODE_MASTER;
  hspi1.Init.Direction = SPI_DIRECTION_2LINES;
  hspi1.Init.DataSize = SPI_DATASIZE_8BIT;
  hspi1.Init.CLKPolarity = SPI_POLARITY_LOW;
  hspi1.Init.CLKPhase = SPI_PHASE_1EDGE;
  hspi1.Init.NSS = SPI_NSS_SOFT;
  hspi1.Init.BaudRatePrescaler = SPI_BAUDRATEPRESCALER_2;
  hspi1.Init.FirstBit = SPI_FIRSTBIT_MSB;
  hspi1.Init.TIMode = SPI_TIMODE_DISABLE;
  hspi1.Init.CRCCalculation = SPI_CRCCALCULATION_DISABLE;
  hspi1.Init.CRCPolynomial = 10;
  if (HAL_SPI_Init(&hspi1) != HAL_OK)
  {
    Error_Handler();
  }

}

static void MX_SPI4_Init(void)
{

  /* SPI4 parameter configuration*/
  hspi4.Instance = SPI4;
  hspi4.Init.Mode = SPI_MODE_MASTER;
  hspi4.Init.Direction = SPI_DIRECTION_2LINES;
  hspi4.Init.DataSize = SPI_DATASIZE_8BIT;
  hspi4.Init.CLKPolarity = SPI_POLARITY_LOW;
  hspi4.Init.CLKPhase = SPI_PHASE_1EDGE;
  hspi4.Init.NSS = SPI_NSS_SOFT;
  hspi4.Init.BaudRatePrescaler = SPI_BAUDRATEPRESCALER_128;
  hspi4.Init.FirstBit = SPI_FIRSTBIT_MSB;
  hspi4.Init.TIMode = SPI_TIMODE_DISABLE;
  hspi4.Init.CRCCalculation = SPI_CRCCALCULATION_DISABLE;
  hspi4.Init.CRCPolynomial = 10;
  if (HAL_SPI_Init(&hspi4) != HAL_OK)
  {
    Error_Handler();
  }

}

static void MX_TIM2_Init(void)
{

  TIM_Encoder_InitTypeDef sConfig = {0};
  TIM_MasterConfigTypeDef sMasterConfig = {0};

  htim2.Instance = TIM2;
  htim2.Init.Prescaler = 0;
  htim2.Init.CounterMode = TIM_COUNTERMODE_UP;
  htim2.Init.Period = 65535;
  htim2.Init.ClockDivision = TIM_CLOCKDIVISION_DIV1;
  htim2.Init.AutoReloadPreload = TIM_AUTORELOAD_PRELOAD_DISABLE;
  sConfig.EncoderMode = TIM_ENCODERMODE_TI12;
  sConfig.IC1Polarity = TIM_ICPOLARITY_RISING;
  sConfig.IC1Selection = TIM_ICSELECTION_DIRECTTI;
  sConfig.IC1Prescaler = TIM_ICPSC_DIV1;
  sConfig.IC1Filter = 0;
  sConfig.IC2Polarity = TIM_ICPOLARITY_RISING;
  sConfig.IC2Selection = TIM_ICSELECTION_DIRECTTI;
  sConfig.IC2Prescaler = TIM_ICPSC_DIV1;
  sConfig.IC2Filter = 0;
  if (HAL_TIM_Encoder_Init(&htim2, &sConfig) != HAL_OK)
  {
    Error_Handler();
  }
  sMasterConfig.MasterOutputTrigger = TIM_TRGO_RESET;
  sMasterConfig.MasterSlaveMode = TIM_MASTERSLAVEMODE_DISABLE;
  if (HAL_TIMEx_MasterConfigSynchronization(&htim2, &sMasterConfig) != HAL_OK)
  {
    Error_Handler();
  }

}

static void MX_USART2_UART_Init(void)
{

  huart2.Instance = USART2;
  huart2.Init.BaudRate = 31250;
  huart2.Init.WordLength = UART_WORDLENGTH_8B;
  huart2.Init.StopBits = UART_STOPBITS_1;
  huart2.Init.Parity = UART_PARITY_NONE;
  huart2.Init.Mode = UART_MODE_TX_RX;
  huart2.Init.HwFlowCtl = UART_HWCONTROL_NONE;
  huart2.Init.OverSampling = UART_OVERSAMPLING_16;
  if (HAL_UART_Init(&huart2) != HAL_OK)
  {
    Error_Handler();
  }

}

static void MX_USB_OTG_FS_PCD_Init(void)
{

  hpcd_USB_OTG_FS.Instance = USB_OTG_FS;
  hpcd_USB_OTG_FS.Init.dev_endpoints = 4;
  hpcd_USB_OTG_FS.Init.speed = PCD_SPEED_FULL;
  hpcd_USB_OTG_FS.Init.dma_enable = DISABLE;
  hpcd_USB_OTG_FS.Init.phy_itface = PCD_PHY_EMBEDDED;
  hpcd_USB_OTG_FS.Init.Sof_enable = DISABLE;
  hpcd_USB_OTG_FS.Init.low_power_enable = DISABLE;
  hpcd_USB_OTG_FS.Init.lpm_enable = DISABLE;
  hpcd_USB_OTG_FS.Init.vbus_sensing_enable = ENABLE;
  hpcd_USB_OTG_FS.Init.use_dedicated_ep1 = DISABLE;
  if (HAL_PCD_Init(&hpcd_USB_OTG_FS) != HAL_OK)
  {
    Error_Handler();
  }

}

static void MX_USB_OTG_HS_HCD_Init(void)
{

  hhcd_USB_OTG_HS.Instance = USB_OTG_HS;
  hhcd_USB_OTG_HS.Init.Host_channels = 12;
  hhcd_USB_OTG_HS.Init.speed = HCD_SPEED_FULL;
  hhcd_USB_OTG_HS.Init.dma_enable = DISABLE;
  hhcd_USB_OTG_HS.Init.phy_itface = USB_OTG_EMBEDDED_PHY;
  hhcd_USB_OTG_HS.Init.Sof_enable = DISABLE;
  hhcd_USB_OTG_HS.Init.low_power_enable = DISABLE;
  hhcd_USB_OTG_HS.Init.vbus_sensing_enable = DISABLE;
  hhcd_USB_OTG_HS.Init.use_external_vbus = DISABLE;
  if (HAL_HCD_Init(&hhcd_USB_OTG_HS) != HAL_OK)
  {
    Error_Handler();
  }

}

static void MX_DMA_Init(void)
{

  /* DMA controller clock enable */
  __HAL_RCC_DMA2_CLK_ENABLE();
  __HAL_RCC_DMA1_CLK_ENABLE();

  /* DMA interrupt init */
  /* DMA1_Stream5_IRQn interrupt configuration */
  HAL_NVIC_SetPriority(DMA1_Stream5_IRQn, 5, 0);
  HAL_NVIC_EnableIRQ(DMA1_Stream5_IRQn);
  /* DMA1_Stream6_IRQn interrupt configuration */
  HAL_NVIC_SetPriority(DMA1_Stream6_IRQn, 5, 0);
  HAL_NVIC_EnableIRQ(DMA1_Stream6_IRQn);
  /* DMA2_Stream0_IRQn interrupt configuration */
  HAL_NVIC_SetPriority(DMA2_Stream0_IRQn, 10, 0);
  HAL_NVIC_EnableIRQ(DMA2_Stream0_IRQn);
  /* DMA2_Stream1_IRQn interrupt configuration */
  HAL_NVIC_SetPriority(DMA2_Stream1_IRQn, 5, 0);
  HAL_NVIC_EnableIRQ(DMA2_Stream1_IRQn);
  /* DMA2_Stream4_IRQn interrupt configuration */
  HAL_NVIC_SetPriority(DMA2_Stream4_IRQn, 5, 0);
  HAL_NVIC_EnableIRQ(DMA2_Stream4_IRQn);

}

/* FMC initialization function */
static void MX_FMC_Init(void)
{

  FMC_SDRAM_TimingTypeDef SdramTiming = {0};

  /** Perform the SDRAM1 memory initialization sequence
  */
  hsdram1.Instance = FMC_SDRAM_DEVICE;
  /* hsdram1.Init */
  hsdram1.Init.SDBank = FMC_SDRAM_BANK2;
  hsdram1.Init.ColumnBitsNumber = FMC_SDRAM_COLUMN_BITS_NUM_8;
  hsdram1.Init.RowBitsNumber = FMC_SDRAM_ROW_BITS_NUM_12;
  hsdram1.Init.MemoryDataWidth = FMC_SDRAM_MEM_BUS_WIDTH_16;
  hsdram1.Init.InternalBankNumber = FMC_SDRAM_INTERN_BANKS_NUM_4;
  hsdram1.Init.CASLatency = FMC_SDRAM_CAS_LATENCY_3;
  hsdram1.Init.WriteProtection = FMC_SDRAM_WRITE_PROTECTION_DISABLE;
  hsdram1.Init.SDClockPeriod = FMC_SDRAM_CLOCK_PERIOD_2;
  hsdram1.Init.ReadBurst = FMC_SDRAM_RBURST_ENABLE;
  hsdram1.Init.ReadPipeDelay = FMC_SDRAM_RPIPE_DELAY_0;
  /* SdramTiming */
  SdramTiming.LoadToActiveDelay = 2;
  SdramTiming.ExitSelfRefreshDelay = 6;
  SdramTiming.SelfRefreshTime = 4;
  SdramTiming.RowCycleDelay = 6;
  SdramTiming.WriteRecoveryTime = 2;
  SdramTiming.RPDelay = 2;
  SdramTiming.RCDDelay = 2;

  if (HAL_SDRAM_Init(&hsdram1, &SdramTiming) != HAL_OK)
  {
    Error_Handler( );
  }

}

static void MX_GPIO_Init(void)
{
  GPIO_InitTypeDef GPIO_InitStruct = {0};

  /* GPIO Ports Clock Enable */
  __HAL_RCC_GPIOE_CLK_ENABLE();
  __HAL_RCC_GPIOC_CLK_ENABLE();
  __HAL_RCC_GPIOF_CLK_ENABLE();
  __HAL_RCC_GPIOH_CLK_ENABLE();
  __HAL_RCC_GPIOA_CLK_ENABLE();
  __HAL_RCC_GPIOB_CLK_ENABLE();
  __HAL_RCC_GPIOG_CLK_ENABLE();
  __HAL_RCC_GPIOD_CLK_ENABLE();

  /*Configure GPIO pin Output Level */
  HAL_GPIO_WritePin(GPIOC, EXTSPI_nCS_Pin|FLASH_HOLD_Pin|FLASH_nCS_Pin|DISPLAY_B_Pin
                          |DISPLAY_C_Pin, GPIO_PIN_RESET);

  /*Configure GPIO pin Output Level */
  HAL_GPIO_WritePin(GPIOF, LED_SW1_Pin|LED_SW2_Pin|DISPLAY_G_Pin, GPIO_PIN_RESET);

  /*Configure GPIO pin Output Level */
  HAL_GPIO_WritePin(GPIOB, FLASH_WP_Pin|GATE_OUT_Pin|DISPLAY_DP_Pin|CS_CS_Pin
                          |CS_RST_Pin|USB_HOST_PWR_EN_Pin|DISPLAY_F_Pin, GPIO_PIN_RESET);

  /*Configure GPIO pin Output Level */
  HAL_GPIO_WritePin(DISPLAY_A_GPIO_Port, DISPLAY_A_Pin, GPIO_PIN_SET);

  /*Configure GPIO pin Output Level */
  HAL_GPIO_WritePin(DISPLAY_D_GPIO_Port, DISPLAY_D_Pin, GPIO_PIN_RESET);

  /*Configure GPIO pin Output Level */
  HAL_GPIO_WritePin(DISPLAY_E_GPIO_Port, DISPLAY_E_Pin, GPIO_PIN_RESET);

  /*Configure GPIO pins : PC13 PC14 PC7 PC11 */
  GPIO_InitStruct.Pin = GPIO_PIN_13|GPIO_PIN_14|GPIO_PIN_7|GPIO_PIN_11;
  GPIO_InitStruct.Mode = GPIO_MODE_ANALOG;
  GPIO_InitStruct.Pull = GPIO_NOPULL;
  HAL_GPIO_Init(GPIOC, &GPIO_InitStruct);

  /*Configure GPIO pins : EXTSPI_nCS_Pin FLASH_HOLD_Pin FLASH_nCS_Pin DISPLAY_A_Pin
                           DISPLAY_B_Pin DISPLAY_C_Pin */
  GPIO_InitStruct.Pin = EXTSPI_nCS_Pin|FLASH_HOLD_Pin|FLASH_nCS_Pin|DISPLAY_A_Pin
                          |DISPLAY_B_Pin|DISPLAY_C_Pin;
  GPIO_InitStruct.Mode = GPIO_MODE_OUTPUT_PP;
  GPIO_InitStruct.Pull = GPIO_NOPULL;
  GPIO_InitStruct.Speed = GPIO_SPEED_FREQ_LOW;
  HAL_GPIO_Init(GPIOC, &GPIO_InitStruct);

  /*Configure GPIO pin : PF6 */
  GPIO_InitStruct.Pin = GPIO_PIN_6;
  GPIO_InitStruct.Mode = GPIO_MODE_ANALOG;
  GPIO_InitStruct.Pull = GPIO_NOPULL;
  HAL_GPIO_Init(GPIOF, &GPIO_InitStruct);

  /*Configure GPIO pins : LED_SW1_Pin LED_SW2_Pin DISPLAY_G_Pin */
  GPIO_InitStruct.Pin = LED_SW1_Pin|LED_SW2_Pin|DISPLAY_G_Pin;
  GPIO_InitStruct.Mode = GPIO_MODE_OUTPUT_PP;
  GPIO_InitStruct.Pull = GPIO_NOPULL;
  GPIO_InitStruct.Speed = GPIO_SPEED_FREQ_LOW;
  HAL_GPIO_Init(GPIOF, &GPIO_InitStruct);

  /*Configure GPIO pins : FLASH_WP_Pin GATE_OUT_Pin DISPLAY_DP_Pin CS_CS_Pin
                           CS_RST_Pin USB_HOST_PWR_EN_Pin DISPLAY_F_Pin */
  GPIO_InitStruct.Pin = FLASH_WP_Pin|GATE_OUT_Pin|DISPLAY_DP_Pin|CS_CS_Pin
                          |CS_RST_Pin|USB_HOST_PWR_EN_Pin|DISPLAY_F_Pin;
  GPIO_InitStruct.Mode = GPIO_MODE_OUTPUT_PP;
  GPIO_InitStruct.Pull = GPIO_NOPULL;
  GPIO_InitStruct.Speed = GPIO_SPEED_FREQ_LOW;
  HAL_GPIO_Init(GPIOB, &GPIO_InitStruct);

  /*Configure GPIO pin : USB_HOST_PWR_FAULT_Pin */
  GPIO_InitStruct.Pin = USB_HOST_PWR_FAULT_Pin;
  GPIO_InitStruct.Mode = GPIO_MODE_INPUT;
  GPIO_InitStruct.Pull = GPIO_PULLUP;
  HAL_GPIO_Init(USB_HOST_PWR_FAULT_GPIO_Port, &GPIO_InitStruct);

  /*Configure GPIO pins : PD11 PD12 PD13 PD3
                           PD4 PD5 PD7 */
  GPIO_InitStruct.Pin = GPIO_PIN_11|GPIO_PIN_12|GPIO_PIN_13|GPIO_PIN_3
                          |GPIO_PIN_4|GPIO_PIN_5|GPIO_PIN_7;
  GPIO_InitStruct.Mode = GPIO_MODE_ANALOG;
  GPIO_InitStruct.Pull = GPIO_NOPULL;
  HAL_GPIO_Init(GPIOD, &GPIO_InitStruct);

  /*Configure GPIO pins : PG2 PG3 PG6 PG7
                           PG10 PG11 PG12 PG13
                           PG14 */
  GPIO_InitStruct.Pin = GPIO_PIN_2|GPIO_PIN_3|GPIO_PIN_6|GPIO_PIN_7
                          |GPIO_PIN_10|GPIO_PIN_11|GPIO_PIN_12|GPIO_PIN_13
                          |GPIO_PIN_14;
  GPIO_InitStruct.Mode = GPIO_MODE_ANALOG;
  GPIO_InitStruct.Pull = GPIO_NOPULL;
  HAL_GPIO_Init(GPIOG, &GPIO_InitStruct);

  /*Configure GPIO pin : DISPLAY_D_Pin */
  GPIO_InitStruct.Pin = DISPLAY_D_Pin;
  GPIO_InitStruct.Mode = GPIO_MODE_OUTPUT_PP;
  GPIO_InitStruct.Pull = GPIO_NOPULL;
  GPIO_InitStruct.Speed = GPIO_SPEED_FREQ_LOW;
  HAL_GPIO_Init(DISPLAY_D_GPIO_Port, &GPIO_InitStruct);

  /*Configure GPIO pin : PA10 */
  GPIO_InitStruct.Pin = GPIO_PIN_10;
  GPIO_InitStruct.Mode = GPIO_MODE_ANALOG;
  GPIO_InitStruct.Pull = GPIO_NOPULL;
  HAL_GPIO_Init(GPIOA, &GPIO_InitStruct);

  /*Configure GPIO pin : SW2_Pin */
  GPIO_InitStruct.Pin = SW2_Pin;
  GPIO_InitStruct.Mode = GPIO_MODE_IT_RISING_FALLING;
  GPIO_InitStruct.Pull = GPIO_PULLUP;
  HAL_GPIO_Init(SW2_GPIO_Port, &GPIO_InitStruct);

  /*Configure GPIO pin : ENC_SW_Pin */
  GPIO_InitStruct.Pin = ENC_SW_Pin;
  GPIO_InitStruct.Mode = GPIO_MODE_INPUT;
  GPIO_InitStruct.Pull = GPIO_PULLUP;
  HAL_GPIO_Init(ENC_SW_GPIO_Port, &GPIO_InitStruct);

  /*Configure GPIO pin : SW1_Pin */
  GPIO_InitStruct.Pin = SW1_Pin;
  GPIO_InitStruct.Mode = GPIO_MODE_IT_RISING_FALLING;
  GPIO_InitStruct.Pull = GPIO_PULLUP;
  HAL_GPIO_Init(SW1_GPIO_Port, &GPIO_InitStruct);

  /*Configure GPIO pin : GATE_IN2_Pin */
  GPIO_InitStruct.Pin = GATE_IN2_Pin;
  GPIO_InitStruct.Mode = GPIO_MODE_IT_RISING_FALLING;
  GPIO_InitStruct.Pull = GPIO_PULLUP;
  HAL_GPIO_Init(GATE_IN2_GPIO_Port, &GPIO_InitStruct);

  /*Configure GPIO pin : DISPLAY_E_Pin */
  GPIO_InitStruct.Pin = DISPLAY_E_Pin;
  GPIO_InitStruct.Mode = GPIO_MODE_OUTPUT_PP;
  GPIO_InitStruct.Pull = GPIO_NOPULL;
  GPIO_InitStruct.Speed = GPIO_SPEED_FREQ_LOW;
  HAL_GPIO_Init(DISPLAY_E_GPIO_Port, &GPIO_InitStruct);

  /*Configure GPIO pins : PB4 PB7 */
  GPIO_InitStruct.Pin = GPIO_PIN_4|GPIO_PIN_7;
  GPIO_InitStruct.Mode = GPIO_MODE_ANALOG;
  GPIO_InitStruct.Pull = GPIO_NOPULL;
  HAL_GPIO_Init(GPIOB, &GPIO_InitStruct);

  /*Configure GPIO pin : GATE_IN1_Pin */
  GPIO_InitStruct.Pin = GATE_IN1_Pin;
  GPIO_InitStruct.Mode = GPIO_MODE_IT_RISING_FALLING;
  GPIO_InitStruct.Pull = GPIO_PULLUP;
  HAL_GPIO_Init(GATE_IN1_GPIO_Port, &GPIO_InitStruct);

  /* EXTI interrupt init*/
  HAL_NVIC_SetPriority(EXTI2_IRQn, 10, 0);
  HAL_NVIC_EnableIRQ(EXTI2_IRQn);

  HAL_NVIC_SetPriority(EXTI9_5_IRQn, 10, 0);
  HAL_NVIC_EnableIRQ(EXTI9_5_IRQn);

  HAL_NVIC_SetPriority(EXTI15_10_IRQn, 10, 0);
  HAL_NVIC_EnableIRQ(EXTI15_10_IRQn);

}

void StartDefaultTask(void const * argument)
{
  /* USER CODE BEGIN 5 */
  setup();

  /* Infinite loop */
  for(;;)
  {
    loop();
  }
  /* USER CODE END 5 */
}

void Error_Handler(void)
{
  /* USER CODE BEGIN Error_Handler_Debug */
  /* User can add his own implementation to report the HAL error return state */
#ifdef DEBUG
  __asm__("BKPT");
#else
  NVIC_SystemReset();
#endif
  /* USER CODE END Error_Handler_Debug */
}

#ifdef  USE_FULL_ASSERT
/**
  * @brief  Reports the name of the source file and the source line number
  *         where the assert_param error has occurred.
  * @param  file: pointer to the source file name
  * @param  line: assert_param error line source number
  * @retval None
  */
void assert_failed(uint8_t *file, uint32_t line)
{
  /* USER CODE BEGIN 6 */
#ifdef DEBUG
  __asm__("BKPT");
#else
  NVIC_SystemReset();
#endif
  /* USER CODE END 6 */
}
#endif /* USE_FULL_ASSERT */

/************************ (C) COPYRIGHT STMicroelectronics *****END OF FILE****/
